VERSION ""

NS_ :

BS_:

BU_: REF_ECU AUT

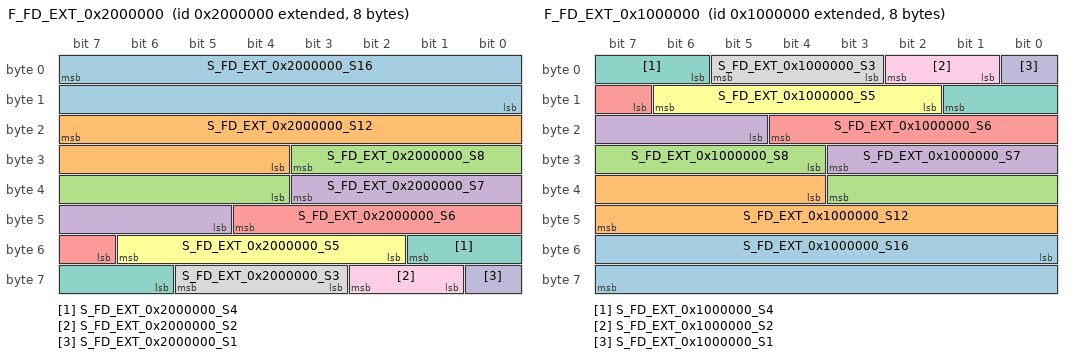
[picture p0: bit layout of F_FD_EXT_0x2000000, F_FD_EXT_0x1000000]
BO_ 2181038080 F_FD_EXT_0x2000000: 8 REF_ECU
 SG_ S_FD_EXT_0x2000000_S16 : 7|16@0- (1,0) [-32768|32767] ""  AUT
 SG_ S_FD_EXT_0x2000000_S12 : 23|12@0- (1,0) [-2048|2047] ""  AUT
 SG_ S_FD_EXT_0x2000000_S8 : 27|8@0- (1,0) [-128|127] ""  AUT
 SG_ S_FD_EXT_0x2000000_S7 : 35|7@0- (1,0) [-64|63] ""  AUT
 SG_ S_FD_EXT_0x2000000_S6 : 44|6@0- (1,0) [-32|31] ""  AUT
 SG_ S_FD_EXT_0x2000000_S5 : 54|5@0- (1,0) [-16|15] ""  AUT
 SG_ S_FD_EXT_0x2000000_S4 : 49|4@0- (1,0) [-8|7] ""  AUT
 SG_ S_FD_EXT_0x2000000_S3 : 61|3@0- (1,0) [-4|3] ""  AUT
 SG_ S_FD_EXT_0x2000000_S2 : 58|2@0- (1,0) [-2|1] ""  AUT
 SG_ S_FD_EXT_0x2000000_S1 : 56|1@0- (1,0) [-1|0] ""  AUT

BO_ 2181038081 F_FD_EXT_0x2000001: 1 REF_ECU
 SG_ S_FD_EXT_0x2000001_S8 : 7|8@0- (1,0) [-128|127] ""  AUT

BO_ 2181038082 F_FD_EXT_0x2000002: 2 REF_ECU
 SG_ S_FD_EXT_0x2000002_S16 : 7|16@0- (1,0) [-32768|32767] ""  AUT

BO_ 2181038083 F_FD_EXT_0x2000003: 3 REF_ECU
 SG_ S_FD_EXT_0x2000003_S24 : 7|24@0- (1,0) [-8388608|8388607] ""  AUT

BO_ 2181038084 F_FD_EXT_0x2000004: 4 REF_ECU
 SG_ S_FD_EXT_0x2000004_S32 : 7|32@0+ (1,0) [0|4294967295] ""  AUT

BO_ 2181038085 F_FD_EXT_0x2000005: 5 REF_ECU
 SG_ S_FD_EXT_0x2000005_S8 : 39|8@0+ (1,0) [0|255] ""  AUT
 SG_ S_FD_EXT_0x2000005_S32 : 7|32@0- (1,0) [-2147483648|2147483647] ""  AUT

BO_ 2181038086 F_FD_EXT_0x2000006: 6 REF_ECU
 SG_ S_FD_EXT_0x2000006_S16 : 39|16@0+ (1,0) [0|65535] ""  AUT
 SG_ S_FD_EXT_0x2000006_S32 : 7|32@0- (1,0) [-2147483648|2147483647] ""  AUT

BO_ 2181038087 F_FD_EXT_0x2000007: 7 REF_ECU
 SG_ S_FD_EXT_0x2000007_S24 : 39|24@0- (1,0) [-8388608|8388607] ""  AUT
 SG_ S_FD_EXT_0x2000007_S32 : 7|32@0- (1,0) [-2147483648|2147483647] ""  AUT

BO_ 2181038088 F_FD_EXT_0x2000008: 8 REF_ECU
 SG_ S_FD_EXT_0x2000008_S32_2 : 39|32@0- (1,0) [-32768|32767] ""  AUT
 SG_ S_FD_EXT_0x2000008_S32_1 : 0|32@1- (1,0) [-32768|32767] ""  AUT

BO_ 2164260864 F_FD_EXT_0x1000000: 8 REF_ECU
 SG_ S_FD_EXT_0x1000000_S16 : 48|16@1+ (1,0) [0|65535] ""  AUT
 SG_ S_FD_EXT_0x1000000_S12 : 36|12@1+ (1,0) [0|4095] ""  AUT
 SG_ S_FD_EXT_0x1000000_S8 : 28|8@1+ (1,0) [0|255] ""  AUT
 SG_ S_FD_EXT_0x1000000_S7 : 21|7@1+ (1,0) [0|127] ""  AUT
 SG_ S_FD_EXT_0x1000000_S6 : 15|6@1+ (1,0) [0|63] ""  AUT
 SG_ S_FD_EXT_0x1000000_S5 : 10|5@1+ (1,0) [0|31] ""  AUT
 SG_ S_FD_EXT_0x1000000_S4 : 6|4@1+ (1,0) [0|15] ""  AUT
 SG_ S_FD_EXT_0x1000000_S3 : 3|3@1+ (1,0) [0|7] ""  AUT
 SG_ S_FD_EXT_0x1000000_S2 : 1|2@1+ (1,0) [0|3] ""  AUT
 SG_ S_FD_EXT_0x1000000_S1 : 0|1@1+ (1,0) [0|1] ""  AUT

BO_ 2164260865 F_FD_EXT_0x1000001: 1 REF_ECU
 SG_ S_FD_EXT_0x1000001_S8 : 0|8@1+ (1,0) [0|255] ""  AUT

BO_ 2164260866 F_FD_EXT_0x1000002: 2 REF_ECU
 SG_ S_FD_EXT_0x1000002_S16 : 0|16@1+ (1,0) [0|65535] ""  AUT

BO_ 2164260867 F_FD_EXT_0x1000003: 3 REF_ECU
 SG_ S_FD_EXT_0x1000003_S24 : 0|24@1+ (1,0) [0|16777200] ""  AUT

BO_ 2164260868 F_FD_EXT_0x1000004: 4 REF_ECU
 SG_ S_FD_EXT_0x1000004_S32 : 0|32@1+ (1,0) [0|4294970000] ""  AUT

BO_ 2164260869 F_FD_EXT_0x1000005: 5 REF_ECU
 SG_ S_FD_EXT_0x1000005_S8 : 32|8@1+ (1,0) [0|255] ""  AUT
 SG_ S_FD_EXT_0x1000005_S32 : 0|32@1+ (1,0) [0|4294970000] ""  AUT

BO_ 2164260870 F_FD_EXT_0x1000006: 6 REF_ECU
 SG_ S_FD_EXT_0x1000006_S16 : 32|16@1+ (1,0) [0|65535] ""  AUT
 SG_ S_FD_EXT_0x1000006_S32 : 0|32@1+ (1,0) [0|4294970000] ""  AUT

BO_ 2164260871 F_FD_EXT_0x1000007: 7 REF_ECU
 SG_ S_FD_EXT_0x1000007_S24 : 32|24@1+ (1,0) [0|16777200] ""  AUT
 SG_ S_FD_EXT_0x1000007_S32 : 0|32@1+ (1,0) [0|4294970000] ""  AUT

BO_ 2164260872 F_FD_EXT_0x1000008: 8 REF_ECU
 SG_ S_FD_EXT_0x1000008_S32_2 : 32|32@1+ (1,0) [0|4294970000] ""  AUT
 SG_ S_FD_EXT_0x1000008_S32_1 : 0|32@1+ (1,0) [0|4294970000] ""  AUT

BO_ 2164260882 F_FD_EXT_0x1000012: 12 REF_ECU
 SG_ S_FD_EXT_0x1000012_S32_3 : 64|32@1+ (1,0) [0|4294970000] ""  AUT
 SG_ S_FD_EXT_0x1000012_S32_2 : 32|32@1+ (1,0) [0|4294970000] ""  AUT
 SG_ S_FD_EXT_0x1000012_S32_1 : 0|32@1+ (1,0) [0|4294970000] ""  AUT

BO_ 2164260886 F_FD_EXT_0x1000016: 16 REF_ECU
 SG_ S_FD_EXT_0x1000016_S32_4 : 96|32@1+ (1,0) [0|4294970000] ""  AUT
 SG_ S_FD_EXT_0x1000016_S32_3 : 64|32@1+ (1,0) [0|4294970000] ""  AUT
 SG_ S_FD_EXT_0x1000016_S32_2 : 32|32@1+ (1,0) [0|4294970000] ""  AUT
 SG_ S_FD_EXT_0x1000016_S32_1 : 0|32@1+ (1,0) [0|4294970000] ""  AUT

BO_ 2164260896 F_FD_EXT_0x1000020: 20 REF_ECU
 SG_ S_FD_EXT_0x1000020_S32_5 : 128|32@1+ (1,0) [0|4294970000] ""  AUT
 SG_ S_FD_EXT_0x1000020_S32_4 : 96|32@1+ (1,0) [0|4294970000] ""  AUT
 SG_ S_FD_EXT_0x1000020_S32_3 : 64|32@1+ (1,0) [0|4294970000] ""  AUT
 SG_ S_FD_EXT_0x1000020_S32_2 : 32|32@1+ (1,0) [0|4294970000] ""  AUT
 SG_ S_FD_EXT_0x1000020_S32_1 : 0|32@1+ (1,0) [0|4294970000] ""  AUT

BO_ 2164260900 F_FD_EXT_0x1000024: 24 REF_ECU
 SG_ S_FD_EXT_0x1000024_S32_6 : 160|32@1+ (1,0) [0|4294970000] ""  AUT
 SG_ S_FD_EXT_0x1000024_S32_5 : 128|32@1+ (1,0) [0|4294970000] ""  AUT
 SG_ S_FD_EXT_0x1000024_S32_4 : 96|32@1+ (1,0) [0|4294970000] ""  AUT
 SG_ S_FD_EXT_0x1000024_S32_3 : 64|32@1+ (1,0) [0|4294970000] ""  AUT
 SG_ S_FD_EXT_0x1000024_S32_2 : 32|32@1+ (1,0) [0|4294970000] ""  AUT
 SG_ S_FD_EXT_0x1000024_S32_1 : 0|32@1+ (1,0) [0|4294970000] ""  AUT

BO_ 2164260914 F_FD_EXT_0x1000032: 32 REF_ECU
 SG_ S_FD_EXT_0x1000032_S32_8 : 224|32@1+ (1,0) [0|4294970000] ""  AUT
 SG_ S_FD_EXT_0x1000032_S32_7 : 192|32@1+ (1,0) [0|4294970000] ""  AUT
 SG_ S_FD_EXT_0x1000032_S32_6 : 160|32@1+ (1,0) [0|4294970000] ""  AUT
 SG_ S_FD_EXT_0x1000032_S32_5 : 128|32@1+ (1,0) [0|4294970000] ""  AUT
 SG_ S_FD_EXT_0x1000032_S32_4 : 96|32@1+ (1,0) [0|4294970000] ""  AUT
 SG_ S_FD_EXT_0x1000032_S32_3 : 64|32@1+ (1,0) [0|4294970000] ""  AUT
 SG_ S_FD_EXT_0x1000032_S32_2 : 32|32@1+ (1,0) [0|4294970000] ""  AUT
 SG_ S_FD_EXT_0x1000032_S32_1 : 0|32@1+ (1,0) [0|4294970000] ""  AUT

BO_ 2164260936 F_FD_EXT_0x1000048: 48 REF_ECU
 SG_ S_FD_EXT_0x1000048_S32_12 : 352|32@1+ (1,0) [0|4294970000] ""  AUT
 SG_ S_FD_EXT_0x1000048_S32_11 : 320|32@1+ (1,0) [0|4294970000] ""  AUT
 SG_ S_FD_EXT_0x1000048_S32_10 : 288|32@1+ (1,0) [0|4294970000] ""  AUT
 SG_ S_FD_EXT_0x1000048_S32_9 : 256|32@1+ (1,0) [0|4294970000] ""  AUT
 SG_ S_FD_EXT_0x1000048_S32_8 : 224|32@1+ (1,0) [0|4294970000] ""  AUT
 SG_ S_FD_EXT_0x1000048_S32_7 : 192|32@1+ (1,0) [0|4294970000] ""  AUT
 SG_ S_FD_EXT_0x1000048_S32_6 : 160|32@1+ (1,0) [0|4294970000] ""  AUT
 SG_ S_FD_EXT_0x1000048_S32_5 : 128|32@1+ (1,0) [0|4294970000] ""  AUT
 SG_ S_FD_EXT_0x1000048_S32_4 : 96|32@1+ (1,0) [0|4294970000] ""  AUT
 SG_ S_FD_EXT_0x1000048_S32_3 : 64|32@1+ (1,0) [0|4294970000] ""  AUT
 SG_ S_FD_EXT_0x1000048_S32_2 : 32|32@1+ (1,0) [0|4294970000] ""  AUT
 SG_ S_FD_EXT_0x1000048_S32_1 : 0|32@1+ (1,0) [0|4294970000] ""  AUT

BO_ 2164260964 F_FD_EXT_0x1000064: 64 REF_ECU
 SG_ S_FD_EXT_0x1000064_S32_16 : 480|32@1+ (1,0) [0|4294970000] ""  AUT
 SG_ S_FD_EXT_0x1000064_S32_15 : 448|32@1+ (1,0) [0|4294970000] ""  AUT
 SG_ S_FD_EXT_0x1000064_S32_14 : 416|32@1+ (1,0) [0|4294970000] ""  AUT
 SG_ S_FD_EXT_0x1000064_S32_13 : 384|32@1+ (1,0) [0|4294970000] ""  AUT
 SG_ S_FD_EXT_0x1000064_S32_12 : 352|32@1+ (1,0) [0|4294970000] ""  AUT
 SG_ S_FD_EXT_0x1000064_S32_11 : 320|32@1+ (1,0) [0|4294970000] ""  AUT
 SG_ S_FD_EXT_0x1000064_S32_10 : 288|32@1+ (1,0) [0|4294970000] ""  AUT
 SG_ S_FD_EXT_0x1000064_S32_9 : 256|32@1+ (1,0) [0|4294970000] ""  AUT
 SG_ S_FD_EXT_0x1000064_S32_8 : 224|32@1+ (1,0) [0|4294970000] ""  AUT
 SG_ S_FD_EXT_0x1000064_S32_7 : 192|32@1+ (1,0) [0|4294970000] ""  AUT
 SG_ S_FD_EXT_0x1000064_S32_6 : 160|32@1+ (1,0) [0|4294970000] ""  AUT
 SG_ S_FD_EXT_0x1000064_S32_5 : 128|32@1+ (1,0) [0|4294970000] ""  AUT
 SG_ S_FD_EXT_0x1000064_S32_4 : 96|32@1+ (1,0) [0|4294970000] ""  AUT
 SG_ S_FD_EXT_0x1000064_S32_3 : 64|32@1+ (1,0) [0|4294970000] ""  AUT
 SG_ S_FD_EXT_0x1000064_S32_2 : 32|32@1+ (1,0) [0|4294970000] ""  AUT
 SG_ S_FD_EXT_0x1000064_S32_1 : 0|32@1+ (1,0) [0|4294970000] ""  AUT

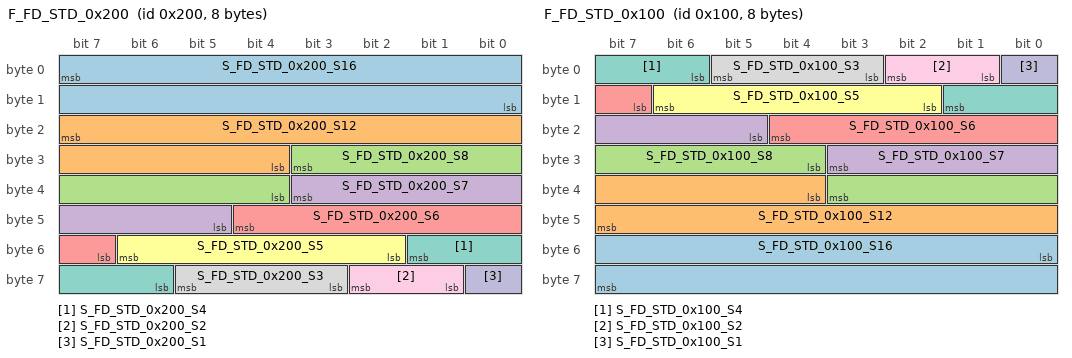
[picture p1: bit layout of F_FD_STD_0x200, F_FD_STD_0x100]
BO_ 512 F_FD_STD_0x200: 8 REF_ECU
 SG_ S_FD_STD_0x200_S16 : 7|16@0- (1,0) [-32768|32767] ""  AUT
 SG_ S_FD_STD_0x200_S12 : 23|12@0- (1,0) [-2048|2047] ""  AUT
 SG_ S_FD_STD_0x200_S8 : 27|8@0- (1,0) [-128|127] ""  AUT
 SG_ S_FD_STD_0x200_S7 : 35|7@0- (1,0) [-64|63] ""  AUT
 SG_ S_FD_STD_0x200_S6 : 44|6@0- (1,0) [-32|31] ""  AUT
 SG_ S_FD_STD_0x200_S5 : 54|5@0- (1,0) [-16|15] ""  AUT
 SG_ S_FD_STD_0x200_S4 : 49|4@0- (1,0) [-8|7] ""  AUT
 SG_ S_FD_STD_0x200_S3 : 61|3@0- (1,0) [-4|3] ""  AUT
 SG_ S_FD_STD_0x200_S2 : 58|2@0- (1,0) [-2|1] ""  AUT
 SG_ S_FD_STD_0x200_S1 : 56|1@0- (1,0) [-1|0] ""  AUT

BO_ 513 F_FD_STD_0x201: 1 REF_ECU
 SG_ S_FD_STD_0x201_S8 : 7|8@0- (1,0) [-128|127] ""  AUT

BO_ 514 F_FD_STD_0x202: 2 REF_ECU
 SG_ S_FD_STD_0x202_S16 : 7|16@0- (1,0) [-32768|32767] ""  AUT

BO_ 515 F_FD_STD_0x203: 3 REF_ECU
 SG_ S_FD_STD_0x203_S24 : 7|24@0- (1,0) [-8388608|8388607] ""  AUT

BO_ 516 F_FD_STD_0x204: 4 REF_ECU
 SG_ S_FD_STD_0x204_S32 : 7|32@0+ (1,0) [0|4294967295] ""  AUT

BO_ 517 F_FD_STD_0x205: 5 REF_ECU
 SG_ S_FD_STD_0x205_S8 : 39|8@0+ (1,0) [0|255] ""  AUT
 SG_ S_FD_STD_0x205_S32 : 7|32@0- (1,0) [-2147483648|2147483647] ""  AUT

BO_ 518 F_FD_STD_0x206: 6 REF_ECU
 SG_ S_FD_STD_0x206_S16 : 39|16@0+ (1,0) [0|65535] ""  AUT
 SG_ S_FD_STD_0x206_S32 : 7|32@0- (1,0) [-2147483648|2147483647] ""  AUT

BO_ 519 F_FD_STD_0x207: 7 REF_ECU
 SG_ S_FD_STD_0x207_S24 : 39|24@0- (1,0) [-8388608|8388607] ""  AUT
 SG_ S_FD_STD_0x207_S32 : 7|32@0- (1,0) [-2147483648|2147483647] ""  AUT

BO_ 520 F_FD_STD_0x208: 8 REF_ECU
 SG_ S_FD_STD_0x208_S32_2 : 39|32@0- (1,0) [-32768|32767] ""  AUT
 SG_ S_FD_STD_0x208_S32_1 : 0|32@1- (1,0) [-32768|32767] ""  AUT

BO_ 256 F_FD_STD_0x100: 8 REF_ECU
 SG_ S_FD_STD_0x100_S16 : 48|16@1+ (1,0) [0|65535] ""  AUT
 SG_ S_FD_STD_0x100_S12 : 36|12@1+ (1,0) [0|4095] ""  AUT
 SG_ S_FD_STD_0x100_S8 : 28|8@1+ (1,0) [0|255] ""  AUT
 SG_ S_FD_STD_0x100_S7 : 21|7@1+ (1,0) [0|127] ""  AUT
 SG_ S_FD_STD_0x100_S6 : 15|6@1+ (1,0) [0|63] ""  AUT
 SG_ S_FD_STD_0x100_S5 : 10|5@1+ (1,0) [0|31] ""  AUT
 SG_ S_FD_STD_0x100_S4 : 6|4@1+ (1,0) [0|15] ""  AUT
 SG_ S_FD_STD_0x100_S3 : 3|3@1+ (1,0) [0|7] ""  AUT
 SG_ S_FD_STD_0x100_S2 : 1|2@1+ (1,0) [0|3] ""  AUT
 SG_ S_FD_STD_0x100_S1 : 0|1@1+ (1,0) [0|1] ""  AUT

BO_ 257 F_FD_STD_0x101: 1 REF_ECU
 SG_ S_FD_STD_0x101_S8 : 0|8@1+ (1,0) [0|255] ""  AUT

BO_ 258 F_FD_STD_0x102: 2 REF_ECU
 SG_ S_FD_STD_0x102_S16 : 0|16@1+ (1,0) [0|65535] ""  AUT

BO_ 259 F_FD_STD_0x103: 3 REF_ECU
 SG_ S_FD_STD_0x103_S24 : 0|24@1+ (1,0) [0|16777200] ""  AUT

BO_ 260 F_FD_STD_0x104: 4 REF_ECU
 SG_ S_FD_STD_0x104_S32 : 0|32@1+ (1,0) [0|4294970000] ""  AUT

BO_ 261 F_FD_STD_0x105: 5 REF_ECU
 SG_ S_FD_STD_0x105_S8 : 32|8@1+ (1,0) [0|255] ""  AUT
 SG_ S_FD_STD_0x105_S32 : 0|32@1+ (1,0) [0|4294970000] ""  AUT

BO_ 262 F_FD_STD_0x106: 6 REF_ECU
 SG_ S_FD_STD_0x106_S16 : 32|16@1+ (1,0) [0|65535] ""  AUT
 SG_ S_FD_STD_0x106_S32 : 0|32@1+ (1,0) [0|4294970000] ""  AUT

BO_ 263 F_FD_STD_0x107: 7 REF_ECU
 SG_ S_FD_STD_0x107_S24 : 32|24@1+ (1,0) [0|16777200] ""  AUT
 SG_ S_FD_STD_0x107_S32 : 0|32@1+ (1,0) [0|4294970000] ""  AUT

BO_ 264 F_FD_STD_0x108: 8 REF_ECU
 SG_ S_FD_STD_0x108_S32_2 : 32|32@1+ (1,0) [0|4294970000] ""  AUT
 SG_ S_FD_STD_0x108_S32_1 : 0|32@1+ (1,0) [0|4294970000] ""  AUT

BO_ 274 F_FD_STD_0x112: 12 REF_ECU
 SG_ S_FD_STD_0x112_S32_3 : 64|32@1+ (1,0) [0|4294970000] ""  AUT
 SG_ S_FD_STD_0x112_S32_2 : 32|32@1+ (1,0) [0|4294970000] ""  AUT
 SG_ S_FD_STD_0x112_S32_1 : 0|32@1+ (1,0) [0|4294970000] ""  AUT

BO_ 278 F_FD_STD_0x116: 16 REF_ECU
 SG_ S_FD_STD_0x116_S32_4 : 96|32@1+ (1,0) [0|4294970000] ""  AUT
 SG_ S_FD_STD_0x116_S32_3 : 64|32@1+ (1,0) [0|4294970000] ""  AUT
 SG_ S_FD_STD_0x116_S32_2 : 32|32@1+ (1,0) [0|4294970000] ""  AUT
 SG_ S_FD_STD_0x116_S32_1 : 0|32@1+ (1,0) [0|4294970000] ""  AUT

BO_ 288 F_FD_STD_0x120: 20 REF_ECU
 SG_ S_FD_STD_0x120_S32_5 : 128|32@1+ (1,0) [0|4294970000] ""  AUT
 SG_ S_FD_STD_0x120_S32_4 : 96|32@1+ (1,0) [0|4294970000] ""  AUT
 SG_ S_FD_STD_0x120_S32_3 : 64|32@1+ (1,0) [0|4294970000] ""  AUT
 SG_ S_FD_STD_0x120_S32_2 : 32|32@1+ (1,0) [0|4294970000] ""  AUT
 SG_ S_FD_STD_0x120_S32_1 : 0|32@1+ (1,0) [0|4294970000] ""  AUT

BO_ 292 F_FD_STD_0x124: 24 REF_ECU
 SG_ S_FD_STD_0x124_S32_6 : 160|32@1+ (1,0) [0|4294970000] ""  AUT
 SG_ S_FD_STD_0x124_S32_5 : 128|32@1+ (1,0) [0|4294970000] ""  AUT
 SG_ S_FD_STD_0x124_S32_4 : 96|32@1+ (1,0) [0|4294970000] ""  AUT
 SG_ S_FD_STD_0x124_S32_3 : 64|32@1+ (1,0) [0|4294970000] ""  AUT
 SG_ S_FD_STD_0x124_S32_2 : 32|32@1+ (1,0) [0|4294970000] ""  AUT
 SG_ S_FD_STD_0x124_S32_1 : 0|32@1+ (1,0) [0|4294970000] ""  AUT

BO_ 306 F_FD_STD_0x132: 32 REF_ECU
 SG_ S_FD_STD_0x132_S32_8 : 224|32@1+ (1,0) [0|4294970000] ""  AUT
 SG_ S_FD_STD_0x132_S32_7 : 192|32@1+ (1,0) [0|4294970000] ""  AUT
 SG_ S_FD_STD_0x132_S32_6 : 160|32@1+ (1,0) [0|4294970000] ""  AUT
 SG_ S_FD_STD_0x132_S32_5 : 128|32@1+ (1,0) [0|4294970000] ""  AUT
 SG_ S_FD_STD_0x132_S32_4 : 96|32@1+ (1,0) [0|4294970000] ""  AUT
 SG_ S_FD_STD_0x132_S32_3 : 64|32@1+ (1,0) [0|4294970000] ""  AUT
 SG_ S_FD_STD_0x132_S32_2 : 32|32@1+ (1,0) [0|4294970000] ""  AUT
 SG_ S_FD_STD_0x132_S32_1 : 0|32@1+ (1,0) [0|4294970000] ""  AUT

BO_ 328 F_FD_STD_0x148: 48 REF_ECU
 SG_ S_FD_STD_0x148_S32_12 : 352|32@1+ (1,0) [0|4294970000] ""  AUT
 SG_ S_FD_STD_0x148_S32_11 : 320|32@1+ (1,0) [0|4294970000] ""  AUT
 SG_ S_FD_STD_0x148_S32_10 : 288|32@1+ (1,0) [0|4294970000] ""  AUT
 SG_ S_FD_STD_0x148_S32_9 : 256|32@1+ (1,0) [0|4294970000] ""  AUT
 SG_ S_FD_STD_0x148_S32_8 : 224|32@1+ (1,0) [0|4294970000] ""  AUT
 SG_ S_FD_STD_0x148_S32_7 : 192|32@1+ (1,0) [0|4294970000] ""  AUT
 SG_ S_FD_STD_0x148_S32_6 : 160|32@1+ (1,0) [0|4294970000] ""  AUT
 SG_ S_FD_STD_0x148_S32_5 : 128|32@1+ (1,0) [0|4294970000] ""  AUT
 SG_ S_FD_STD_0x148_S32_4 : 96|32@1+ (1,0) [0|4294970000] ""  AUT
 SG_ S_FD_STD_0x148_S32_3 : 64|32@1+ (1,0) [0|4294970000] ""  AUT
 SG_ S_FD_STD_0x148_S32_2 : 32|32@1+ (1,0) [0|4294970000] ""  AUT
 SG_ S_FD_STD_0x148_S32_1 : 0|32@1+ (1,0) [0|4294970000] ""  AUT

BO_ 356 F_FD_STD_0x164: 64 REF_ECU
 SG_ S_FD_STD_0x164_S32_16 : 480|32@1+ (1,0) [0|4294970000] ""  AUT
 SG_ S_FD_STD_0x164_S32_15 : 448|32@1+ (1,0) [0|4294970000] ""  AUT
 SG_ S_FD_STD_0x164_S32_14 : 416|32@1+ (1,0) [0|4294970000] ""  AUT
 SG_ S_FD_STD_0x164_S32_13 : 384|32@1+ (1,0) [0|4294970000] ""  AUT
 SG_ S_FD_STD_0x164_S32_12 : 352|32@1+ (1,0) [0|4294970000] ""  AUT
 SG_ S_FD_STD_0x164_S32_11 : 320|32@1+ (1,0) [0|4294970000] ""  AUT
 SG_ S_FD_STD_0x164_S32_10 : 288|32@1+ (1,0) [0|4294970000] ""  AUT
 SG_ S_FD_STD_0x164_S32_9 : 256|32@1+ (1,0) [0|4294970000] ""  AUT
 SG_ S_FD_STD_0x164_S32_8 : 224|32@1+ (1,0) [0|4294970000] ""  AUT
 SG_ S_FD_STD_0x164_S32_7 : 192|32@1+ (1,0) [0|4294970000] ""  AUT
 SG_ S_FD_STD_0x164_S32_6 : 160|32@1+ (1,0) [0|4294970000] ""  AUT
 SG_ S_FD_STD_0x164_S32_5 : 128|32@1+ (1,0) [0|4294970000] ""  AUT
 SG_ S_FD_STD_0x164_S32_4 : 96|32@1+ (1,0) [0|4294970000] ""  AUT
 SG_ S_FD_STD_0x164_S32_3 : 64|32@1+ (1,0) [0|4294970000] ""  AUT
 SG_ S_FD_STD_0x164_S32_2 : 32|32@1+ (1,0) [0|4294970000] ""  AUT
 SG_ S_FD_STD_0x164_S32_1 : 0|32@1+ (1,0) [0|4294970000] ""  AUT

BA_DEF_ BO_  "CANFD_BRS" ENUM  "0","1";
BA_DEF_  "DBName" STRING ;
BA_DEF_  "BusType" STRING ;
BA_DEF_ BO_  "VFrameFormat" ENUM  "StandardCAN","ExtendedCAN","reserved","reserved","reserved","reserved","reserved","reserved","reserved","reserved","reserved","reserved","reserved","reserved","StandardCAN_FD","ExtendedCAN_FD";
BA_DEF_DEF_  "CANFD_BRS" "1";
BA_DEF_DEF_  "DBName" "";
BA_DEF_DEF_  "BusType" "";
BA_DEF_DEF_  "VFrameFormat" "StandardCAN";
BA_ "BusType" "CAN FD";
BA_ "DBName" "CAN_FD";
BA_ "VFrameFormat" BO_ 2181038080 15;
BA_ "VFrameFormat" BO_ 2181038081 15;
BA_ "VFrameFormat" BO_ 2181038082 15;
BA_ "VFrameFormat" BO_ 2181038083 15;
BA_ "VFrameFormat" BO_ 2181038084 15;
BA_ "VFrameFormat" BO_ 2181038085 15;
BA_ "VFrameFormat" BO_ 2181038086 15;
BA_ "VFrameFormat" BO_ 2181038087 15;
BA_ "VFrameFormat" BO_ 2181038088 15;
BA_ "VFrameFormat" BO_ 2164260864 15;
BA_ "VFrameFormat" BO_ 2164260865 15;
BA_ "VFrameFormat" BO_ 2164260866 15;
BA_ "VFrameFormat" BO_ 2164260867 15;
BA_ "VFrameFormat" BO_ 2164260868 15;
BA_ "VFrameFormat" BO_ 2164260869 15;
BA_ "VFrameFormat" BO_ 2164260870 15;
BA_ "VFrameFormat" BO_ 2164260871 15;
BA_ "VFrameFormat" BO_ 2164260872 15;
BA_ "VFrameFormat" BO_ 2164260882 15;
BA_ "VFrameFormat" BO_ 2164260886 15;
BA_ "VFrameFormat" BO_ 2164260896 15;
BA_ "VFrameFormat" BO_ 2164260900 15;
BA_ "VFrameFormat" BO_ 2164260914 15;
BA_ "VFrameFormat" BO_ 2164260936 15;
BA_ "VFrameFormat" BO_ 2164260964 15;
BA_ "VFrameFormat" BO_ 512 14;
BA_ "VFrameFormat" BO_ 513 14;
BA_ "VFrameFormat" BO_ 514 14;
BA_ "VFrameFormat" BO_ 515 14;
BA_ "VFrameFormat" BO_ 516 14;
BA_ "VFrameFormat" BO_ 517 14;
BA_ "VFrameFormat" BO_ 518 14;
BA_ "VFrameFormat" BO_ 519 14;
BA_ "VFrameFormat" BO_ 520 14;
BA_ "VFrameFormat" BO_ 256 14;
BA_ "VFrameFormat" BO_ 257 14;
BA_ "VFrameFormat" BO_ 258 14;
BA_ "VFrameFormat" BO_ 259 14;
BA_ "VFrameFormat" BO_ 260 14;
BA_ "VFrameFormat" BO_ 261 14;
BA_ "VFrameFormat" BO_ 262 14;
BA_ "VFrameFormat" BO_ 263 14;
BA_ "VFrameFormat" BO_ 264 14;
BA_ "VFrameFormat" BO_ 274 14;
BA_ "VFrameFormat" BO_ 278 14;
BA_ "VFrameFormat" BO_ 288 14;
BA_ "VFrameFormat" BO_ 292 14;
BA_ "VFrameFormat" BO_ 306 14;
BA_ "VFrameFormat" BO_ 328 14;
BA_ "VFrameFormat" BO_ 356 14;
SIG_VALTYPE_ 2181038088 S_FD_EXT_0x2000008_S32_2 : 1;
SIG_VALTYPE_ 2181038088 S_FD_EXT_0x2000008_S32_1 : 1;
SIG_VALTYPE_ 520 S_FD_STD_0x208_S32_2 : 1;
SIG_VALTYPE_ 520 S_FD_STD_0x208_S32_1 : 1;
